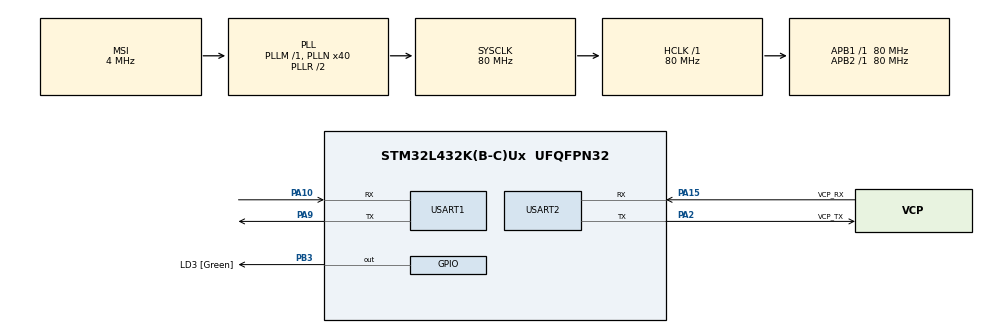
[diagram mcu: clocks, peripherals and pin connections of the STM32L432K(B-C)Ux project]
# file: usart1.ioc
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Mcu.Family=STM32L4
Mcu.Name=STM32L432K(B-C)Ux
Mcu.Package=UFQFPN32
NVIC.PriorityGroup=NVIC_PRIORITYGROUP_4
PA0.GPIO_Label=MCO [High speed clock in]
PA0.Mode=HSE-External-Clock-Source-for-LittleOrca
PA0.Signal=RCC_CK_IN
PA10.Mode=Asynchronous
PA10.Signal=USART1_RX
PA13\ (JTMS-SWDIO).GPIO_Label=SWDIO
PA13\ (JTMS-SWDIO).Mode=Serial_Wire
PA13\ (JTMS-SWDIO).Signal=SYS_JTMS-SWDIO
PA14\ (JTCK-SWCLK).GPIO_Label=SWCLK
PA14\ (JTCK-SWCLK).Mode=Serial_Wire
PA14\ (JTCK-SWCLK).Signal=SYS_JTCK-SWCLK
PA15\ (JTDI).GPIO_Label=VCP_RX
PA15\ (JTDI).Mode=Asynchronous
PA15\ (JTDI).Signal=USART2_RX
PA2.GPIO_Label=VCP_TX
PA2.Mode=Asynchronous
PA2.Signal=USART2_TX
PA9.Mode=Asynchronous
PA9.Signal=USART1_TX
PB3\ (JTDO-TRACESWO).GPIO_Label=LD3 [Green]
PB3\ (JTDO-TRACESWO).Signal=GPIO_Output
PC14-OSC32_IN\ (PC14).Mode=LSE-External-Oscillator
PC14-OSC32_IN\ (PC14).Signal=RCC_OSC32_IN
PC15-OSC32_OUT\ (PC15).Mode=LSE-External-Oscillator
PC15-OSC32_OUT\ (PC15).Signal=RCC_OSC32_OUT
ProjectManager.HeapSize=0x200
ProjectManager.StackSize=0x400
ProjectManager.TargetToolchain=TrueSTUDIO
RCC.AHBFreq_Value=80000000
RCC.APB1Freq_Value=80000000
RCC.APB1TimFreq_Value=80000000
RCC.APB2Freq_Value=80000000
RCC.APB2TimFreq_Value=80000000
RCC.CortexFreq_Value=80000000
RCC.HCLKFreq_Value=80000000
RCC.HSE_VALUE=8000000
RCC.HSI16_VALUE=16000000
RCC.HSI48_VALUE=48000000
RCC.HSI_VALUE=16000000
RCC.MSI_VALUE=4000000
RCC.PLLMUL=RCC_PLLMUL_4
RCC.PLLN=40
RCC.SYSCLKFreq_VALUE=80000000
RCC.SYSCLKSource=RCC_SYSCLKSOURCE_PLLCLK
RCC.VCOOutputFreq_Value=160000000
USART1.VirtualMode-Asynchronous=VM_ASYNC
USART1.WordLength=WORDLENGTH_8B
USART2.VirtualMode-Asynchronous=VM_ASYNC
board=NUCLEO-L432KC

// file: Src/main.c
/**
  ******************************************************************************
  * @file           : main.c
  * @brief          : Main program body
  ******************************************************************************
  ** This notice applies to any and all portions of this file
  * that are not between comment pairs USER CODE BEGIN and
  * USER CODE END. Other portions of this file, whether
  * inserted by the user or by software development tools
  * are owned by their respective copyright owners.
  *
  * COPYRIGHT(c) 2018 STMicroelectronics
  *
  * Redistribution and use in source and binary forms, with or without modification,
  * are permitted provided that the following conditions are met:
  *   1. Redistributions of source code must retain the above copyright notice,
  *      this list of conditions and the following disclaimer.
  *   2. Redistributions in binary form must reproduce the above copyright notice,
  *      this list of conditions and the following disclaimer in the documentation
  *      and/or other materials provided with the distribution.
  *   3. Neither the name of STMicroelectronics nor the names of its contributors
  *      may be used to endorse or promote products derived from this software
  *      without specific prior written permission.
  *
  * THIS SOFTWARE IS PROVIDED BY THE COPYRIGHT HOLDERS AND CONTRIBUTORS "AS IS"
  * AND ANY EXPRESS OR IMPLIED WARRANTIES, INCLUDING, BUT NOT LIMITED TO, THE
  * IMPLIED WARRANTIES OF MERCHANTABILITY AND FITNESS FOR A PARTICULAR PURPOSE ARE
  * DISCLAIMED. IN NO EVENT SHALL THE COPYRIGHT HOLDER OR CONTRIBUTORS BE LIABLE
  * FOR ANY DIRECT, INDIRECT, INCIDENTAL, SPECIAL, EXEMPLARY, OR CONSEQUENTIAL
  * DAMAGES (INCLUDING, BUT NOT LIMITED TO, PROCUREMENT OF SUBSTITUTE GOODS OR
  * SERVICES; LOSS OF USE, DATA, OR PROFITS; OR BUSINESS INTERRUPTION) HOWEVER
  * CAUSED AND ON ANY THEORY OF LIABILITY, WHETHER IN CONTRACT, STRICT LIABILITY,
  * OR TORT (INCLUDING NEGLIGENCE OR OTHERWISE) ARISING IN ANY WAY OUT OF THE USE
  * OF THIS SOFTWARE, EVEN IF ADVISED OF THE POSSIBILITY OF SUCH DAMAGE.
  *
  ******************************************************************************
  */
#include "main.h"
#include "stm32l4xx_hal.h"

UART_HandleTypeDef huart1;
UART_HandleTypeDef huart2;

/* USER CODE BEGIN PV */
/* Private variables ---------------------------------------------------------*/

/* USER CODE END PV */

void SystemClock_Config(void);
static void MX_GPIO_Init(void);
static void MX_USART2_UART_Init(void);
static void MX_USART1_UART_Init(void);

/* USER CODE BEGIN PFP */
/* Private function prototypes -----------------------------------------------*/

/* USER CODE END PFP */

int main(void)
{

  /* MCU Configuration----------------------------------------------------------*/

  /* Reset of all peripherals, Initializes the Flash interface and the Systick. */
  HAL_Init();

  /* Configure the system clock */
  SystemClock_Config();

  /* Initialize all configured peripherals */
  MX_GPIO_Init();
  MX_USART2_UART_Init();
  MX_USART1_UART_Init();
  /* USER CODE BEGIN 2 */

  uint8_t buffer;

  /* USER CODE END 2 */

  /* Infinite loop */
  while (1)
  {

  /* USER CODE BEGIN 3 */
      // Echoes back in polling mode, 115200bps 8N1
      HAL_StatusTypeDef rc = HAL_UART_Receive(&huart1, &buffer, 1, 50);

      if (rc == HAL_OK) {
          HAL_UART_Transmit(&huart1, &buffer, 1, HAL_MAX_DELAY);
      } else {
          uint8_t dot = '.';
          HAL_UART_Transmit(&huart1, &dot, 1, HAL_MAX_DELAY);
      }
      HAL_GPIO_TogglePin(LD3_GPIO_Port, LD3_Pin);
  }
  /* USER CODE END 3 */

}

void SystemClock_Config(void)
{

  RCC_OscInitTypeDef RCC_OscInitStruct;
  RCC_ClkInitTypeDef RCC_ClkInitStruct;
  RCC_PeriphCLKInitTypeDef PeriphClkInit;

    /**Configure LSE Drive Capability
    */
  __HAL_RCC_LSEDRIVE_CONFIG(RCC_LSEDRIVE_LOW);

    /**Initializes the CPU, AHB and APB busses clocks
    */
  RCC_OscInitStruct.OscillatorType = RCC_OSCILLATORTYPE_LSE|RCC_OSCILLATORTYPE_MSI;
  RCC_OscInitStruct.LSEState = RCC_LSE_ON;
  RCC_OscInitStruct.MSIState = RCC_MSI_ON;
  RCC_OscInitStruct.MSICalibrationValue = 0;
  RCC_OscInitStruct.MSIClockRange = RCC_MSIRANGE_6;
  RCC_OscInitStruct.PLL.PLLState = RCC_PLL_ON;
  RCC_OscInitStruct.PLL.PLLSource = RCC_PLLSOURCE_MSI;
  RCC_OscInitStruct.PLL.PLLM = 1;
  RCC_OscInitStruct.PLL.PLLN = 40;
  RCC_OscInitStruct.PLL.PLLP = RCC_PLLP_DIV7;
  RCC_OscInitStruct.PLL.PLLQ = RCC_PLLQ_DIV2;
  RCC_OscInitStruct.PLL.PLLR = RCC_PLLR_DIV2;
  if (HAL_RCC_OscConfig(&RCC_OscInitStruct) != HAL_OK)
  {
    _Error_Handler(__FILE__, __LINE__);
  }

    /**Initializes the CPU, AHB and APB busses clocks
    */
  RCC_ClkInitStruct.ClockType = RCC_CLOCKTYPE_HCLK|RCC_CLOCKTYPE_SYSCLK
                              |RCC_CLOCKTYPE_PCLK1|RCC_CLOCKTYPE_PCLK2;
  RCC_ClkInitStruct.SYSCLKSource = RCC_SYSCLKSOURCE_PLLCLK;
  RCC_ClkInitStruct.AHBCLKDivider = RCC_SYSCLK_DIV1;
  RCC_ClkInitStruct.APB1CLKDivider = RCC_HCLK_DIV1;
  RCC_ClkInitStruct.APB2CLKDivider = RCC_HCLK_DIV1;

  if (HAL_RCC_ClockConfig(&RCC_ClkInitStruct, FLASH_LATENCY_4) != HAL_OK)
  {
    _Error_Handler(__FILE__, __LINE__);
  }

  PeriphClkInit.PeriphClockSelection = RCC_PERIPHCLK_USART1|RCC_PERIPHCLK_USART2;
  PeriphClkInit.Usart1ClockSelection = RCC_USART1CLKSOURCE_PCLK2;
  PeriphClkInit.Usart2ClockSelection = RCC_USART2CLKSOURCE_PCLK1;
  if (HAL_RCCEx_PeriphCLKConfig(&PeriphClkInit) != HAL_OK)
  {
    _Error_Handler(__FILE__, __LINE__);
  }

    /**Configure the main internal regulator output voltage
    */
  if (HAL_PWREx_ControlVoltageScaling(PWR_REGULATOR_VOLTAGE_SCALE1) != HAL_OK)
  {
    _Error_Handler(__FILE__, __LINE__);
  }

    /**Configure the Systick interrupt time
    */
  HAL_SYSTICK_Config(HAL_RCC_GetHCLKFreq()/1000);

    /**Configure the Systick
    */
  HAL_SYSTICK_CLKSourceConfig(SYSTICK_CLKSOURCE_HCLK);

    /**Enable MSI Auto calibration
    */
  HAL_RCCEx_EnableMSIPLLMode();

  /* SysTick_IRQn interrupt configuration */
  HAL_NVIC_SetPriority(SysTick_IRQn, 0, 0);
}

/* USART1 init function */
static void MX_USART1_UART_Init(void)
{

  huart1.Instance = USART1;
  huart1.Init.BaudRate = 115200;
  huart1.Init.WordLength = UART_WORDLENGTH_8B;
  huart1.Init.StopBits = UART_STOPBITS_1;
  huart1.Init.Parity = UART_PARITY_NONE;
  huart1.Init.Mode = UART_MODE_TX_RX;
  huart1.Init.HwFlowCtl = UART_HWCONTROL_NONE;
  huart1.Init.OverSampling = UART_OVERSAMPLING_16;
  huart1.Init.OneBitSampling = UART_ONE_BIT_SAMPLE_DISABLE;
  huart1.AdvancedInit.AdvFeatureInit = UART_ADVFEATURE_NO_INIT;
  if (HAL_UART_Init(&huart1) != HAL_OK)
  {
    _Error_Handler(__FILE__, __LINE__);
  }

}

/* USART2 init function */
static void MX_USART2_UART_Init(void)
{

  huart2.Instance = USART2;
  huart2.Init.BaudRate = 115200;
  huart2.Init.WordLength = UART_WORDLENGTH_7B;
  huart2.Init.StopBits = UART_STOPBITS_1;
  huart2.Init.Parity = UART_PARITY_NONE;
  huart2.Init.Mode = UART_MODE_TX_RX;
  huart2.Init.HwFlowCtl = UART_HWCONTROL_NONE;
  huart2.Init.OverSampling = UART_OVERSAMPLING_16;
  huart2.Init.OneBitSampling = UART_ONE_BIT_SAMPLE_DISABLE;
  huart2.AdvancedInit.AdvFeatureInit = UART_ADVFEATURE_NO_INIT;
  if (HAL_UART_Init(&huart2) != HAL_OK)
  {
    _Error_Handler(__FILE__, __LINE__);
  }

}

/** Configure pins as
        * Analog
        * Input
        * Output
        * EVENT_OUT
        * EXTI
*/
static void MX_GPIO_Init(void)
{

  GPIO_InitTypeDef GPIO_InitStruct;

  /* GPIO Ports Clock Enable */
  __HAL_RCC_GPIOC_CLK_ENABLE();
  __HAL_RCC_GPIOA_CLK_ENABLE();
  __HAL_RCC_GPIOB_CLK_ENABLE();

  /*Configure GPIO pin Output Level */
  HAL_GPIO_WritePin(LD3_GPIO_Port, LD3_Pin, GPIO_PIN_RESET);

  /*Configure GPIO pin : LD3_Pin */
  GPIO_InitStruct.Pin = LD3_Pin;
  GPIO_InitStruct.Mode = GPIO_MODE_OUTPUT_PP;
  GPIO_InitStruct.Pull = GPIO_NOPULL;
  GPIO_InitStruct.Speed = GPIO_SPEED_FREQ_LOW;
  HAL_GPIO_Init(LD3_GPIO_Port, &GPIO_InitStruct);

}

void _Error_Handler(char *file, int line)
{
  while(1)
  {
  }
}

/************************ (C) COPYRIGHT STMicroelectronics *****END OF FILE****/
